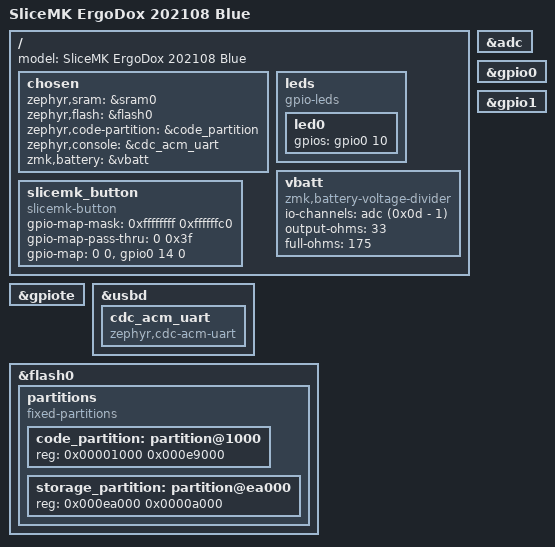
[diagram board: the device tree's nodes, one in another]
/dts-v1/;
#include <nordic/nrf52840_qiaa.dtsi>

/ {
    model = "SliceMK ErgoDox 202108 Blue";

    chosen {
        zephyr,sram = &sram0;
        zephyr,flash = &flash0;
        zephyr,code-partition = &code_partition;
        zephyr,console = &cdc_acm_uart;
        zmk,battery = &vbatt;
    };

    leds {
        compatible = "gpio-leds";
        led0: led0 {
            gpios = <&gpio0 10 GPIO_ACTIVE_HIGH>;
        };
    };

    vbatt: vbatt {
        compatible = "zmk,battery-voltage-divider";
        io-channels = <&adc (0x0d - 1)>;
        output-ohms = <33>;
        full-ohms = <175>;
    };

    slicemk_button: slicemk_button {
        compatible = "slicemk-button";
        #gpio-cells = <2>;
        gpio-map-mask = <0xffffffff 0xffffffc0>;
        gpio-map-pass-thru = <0 0x3f>;
        gpio-map = <0 0 &gpio0 14 0>;
    };
};

&adc {
    status = "okay";
};

&gpiote {
    status = "okay";
};

&gpio0 {
    status = "okay";
};

&gpio1 {
    status = "okay";
};

&usbd {
    status = "okay";
    cdc_acm_uart: cdc_acm_uart {
        compatible = "zephyr,cdc-acm-uart";
    };
};

&flash0 {
    partitions {
        compatible = "fixed-partitions";
        #address-cells = <1>;
        #size-cells = <1>;

        code_partition: partition@1000 {
            reg = <0x00001000 0x000e9000>;
        };

        storage_partition: partition@ea000 {
            reg = <0x000ea000 0x0000a000>;
        };
    };
};
